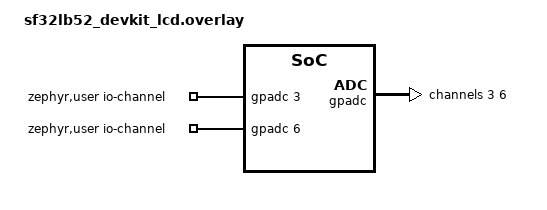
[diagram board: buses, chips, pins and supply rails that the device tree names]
/*
 * SPDX-FileCopyrightText: Copyright The Zephyr Project Contributors
 * SPDX-License-Identifier: Apache-2.0
 */

#include <zephyr/dt-bindings/adc/adc.h>

/ {
	zephyr,user {
		io-channels = <&gpadc 3>, <&gpadc 6>;
	};
};

&pinctrl {
	gpadc_default: gpadc_default {
		group1 {
			pinmux = <PA31_GPADC_CH3>, <PA34_GPADC_CH6>;
		};
	};
};

&gpadc {
	status = "okay";
	pinctrl-0 = <&gpadc_default>;
	pinctrl-names = "default";
	#address-cells = <1>;
	#size-cells = <0>;

	channel@3 {
		reg = <3>;
		zephyr,gain = "ADC_GAIN_1";
		zephyr,reference = "ADC_REF_INTERNAL";
		zephyr,acquisition-time = <ADC_ACQ_TIME_DEFAULT>;
		zephyr,resolution = <12>;
	};

	channel@6 {
		reg = <6>;
		zephyr,gain = "ADC_GAIN_1";
		zephyr,reference = "ADC_REF_INTERNAL";
		zephyr,acquisition-time = <ADC_ACQ_TIME_DEFAULT>;
		zephyr,resolution = <12>;
	};
};
